# nrf54ls05b_enga_application register map
Vendor: Nordic Semiconductor; Series: nrf54l; File version: 1
CPU: CM33 r0p4, little endian, no MPU, no FPU, 3 interrupt priority bits, 270 interrupts
Registers are 32-bit, read-write, reset 0x0 unless marked. A register's access mark holds for its fields unless they carry their own. Offsets are from the block's base; [hi:lo] are bit positions; lines under a group give offsets from that group; {n}, {i} and the like mark numbered series; 'fields as' and 'values as' point back to an identical list.

## GLOBAL_ECCRAMC — ECCRAMC peripheral
Base 0x4007D000
0x00 TASKS_CLEAR wo — Clear ECC SECCOUNT and DEDCOUNT registers
  [0] TASKS_CLEAR
    1=Trigger task
0x100 EVENTS_SEC — SEC event occurred
  [0] EVENTS_SEC
    0=NotGenerated (Event not generated); 1=Generated (Event generated)
0x104 EVENTS_DED — DED event occurred
  [0] EVENTS_DED
    values as EVENTS_SEC.EVENTS_SEC
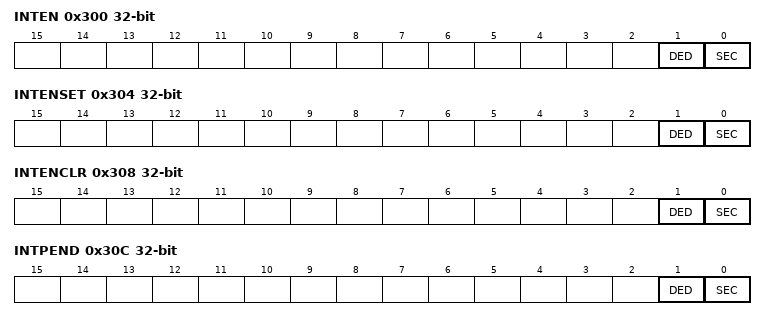
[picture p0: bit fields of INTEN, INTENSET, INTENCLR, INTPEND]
0x300 INTEN — Enable or disable interrupt
  [1] DED — Enable or disable interrupt for event DED
    0=Disabled; 1=Enabled
  [0] SEC — Enable or disable interrupt for event SEC
    0=Disabled; 1=Enabled
0x304 INTENSET — Enable interrupt
  [1] DED — Write '1' to enable interrupt for event DED
    on read: 0=Disabled (Read: Disabled); 1=Enabled (Read: Enabled) | on write: 1=Set (Enable)
  [0] SEC — Write '1' to enable interrupt for event SEC
    values as DED
0x308 INTENCLR — Disable interrupt
  [1] DED — Write '1' to disable interrupt for event DED
    on read: 0=Disabled (Read: Disabled); 1=Enabled (Read: Enabled) | on write: 1=Clear (Disable)
  [0] SEC — Write '1' to disable interrupt for event SEC
    values as DED
0x30C INTPEND ro — Pending interrupts
  [1] DED — Read pending status of interrupt for event DED
    on read: 0=NotPending (Read: Not pending); 1=Pending (Read: Pending)
  [0] SEC — Read pending status of interrupt for event SEC
    values as DED
0x400 ECCDIS — Disable ECC for RAM
  [0] DISABLED — ECC is disabled
    0=Enabled; 1=Disabled
0x404 ECCMON group — ECC monitoring registers
  0x00 ENABLE — Enable monitoring counters
    [0] ENABLED — ECC monitoring counters are enabled
      1=Enabled; 0=Disabled
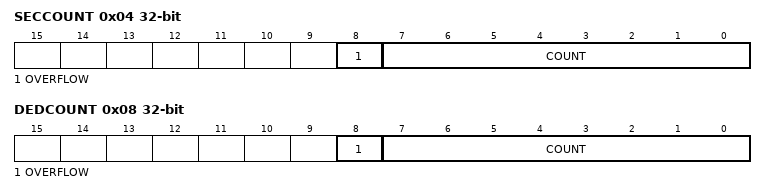
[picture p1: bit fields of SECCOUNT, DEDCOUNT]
  0x04 SECCOUNT ro — Number of single-bit errors corrected
    [8] OVERFLOW — Overflow flag
    [7:0] COUNT — Counter value
  0x08 DEDCOUNT ro — Number of non-correctable bit errors
    [8] OVERFLOW — Overflow flag
    [7:0] COUNT — Counter value
  0x0C ECCPARITY ro — ECC parity bits
    [31:0] PARITY — Parity bits value

## GLOBAL_SREGS00 — Spare registers
Base 0x4007E000
Same registers: GLOBAL_SREGS10 0x4008C000, GLOBAL_SREGS20 0x400E6000, GLOBAL_SREGS30 0x4010F000
{0x500+4i} REG[{i}] (i=0..1) — Description collection: Spare register n
  [31:0] VALUE
0x580 TESTREG — Test special register
  [3:0] TESTFIELD
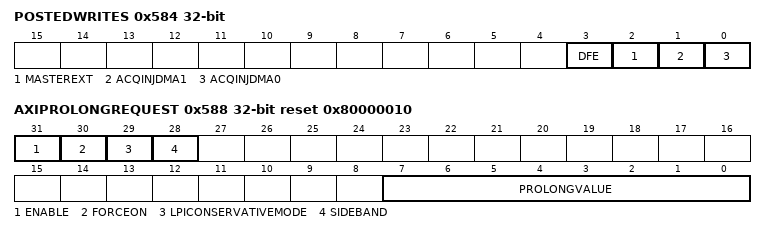
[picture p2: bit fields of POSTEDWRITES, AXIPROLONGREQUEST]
0x584 POSTEDWRITES — Enable or disable posted writes functionality for specific AXI/AHB bus masters
  [all] fields
    0=Disabled (Disable posted writes); 1=Enabled (Enable posted writes)
  [3] DFE — Disable or enable posted writes for Radio AHB for Direction Finding
  [2] MASTEREXT — Disable or enable posted writes for Radio AHB for Radio packets
  [1] ACQINJDMA1 — Disable or enable posted writes for Radio ACQINJDMA1
  [0] ACQINJDMA0 — Disable or enable posted writes for Radio ACQINJDMA0
0x588 AXIPROLONGREQUEST reset 0x80000010 — Configuration of the AxiRequestProlonger module.
  [31] ENABLE — Disable or enable the prolong functionality
    0=Disabled (Disable prolong functionality); 1=Enabled (Enable prolong functionality)
  [30] FORCEON — Disable or enable constant prolong request
    0=Disabled (Disable FORCEON); 1=Enabled (Enable FORCEON)
  [29] LPICONSERVATIVEMODE — Disable or enable LPI conservative mode
    values as the fields of POSTEDWRITES
  [28] SIDEBAND — Disable or enable additional sideband request
    0=Disabled (Disable sideband); 1=Enabled (Enable sideband)
  [7:0] PROLONGVALUE — Number of additional clocks the request is prolonged
0x58C RADIOSIDEBANDREQUEST — Sideband request from Radio to LRC.
  [0] SIDEBAND — Disable or enable sideband request for Radio
    0=Disabled (Disable sideband request); 1=Enabled (Enable sideband request)
{0x600+4i} MAINREG[{i}] (i=0..0) — Description collection: Spare register n in PD_MAIN
  [7:0] VALUE
{0x700+4i} AOREG[{i}] (i=0..0) — Description collection: Spare register n in PD_AO
  [3:0] VALUE
